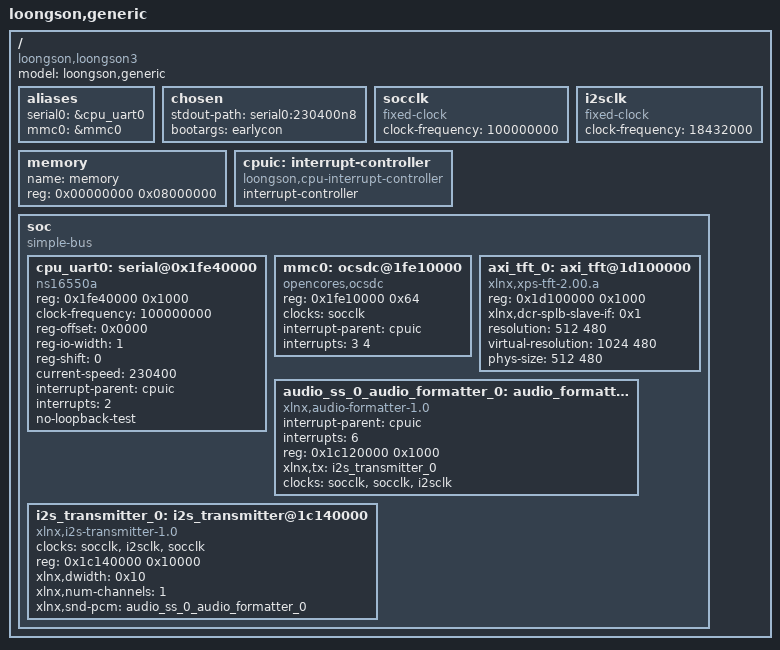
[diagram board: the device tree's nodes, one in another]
/dts-v1/;
/{
    model = "loongson,generic";
    compatible = "loongson,loongson3";
    #address-cells = <1>;
    #size-cells = <1>;

    aliases {
        serial0 = &cpu_uart0;
        mmc0 = &mmc0;
    };

    chosen {
        stdout-path = "serial0:230400n8";
        bootargs = "earlycon";
    };

	socclk: socclk {
		compatible = "fixed-clock";
		clock-frequency = <100000000>;
		#clock-cells = <0>;
	};

	i2sclk: i2sclk {
		compatible = "fixed-clock";
		clock-frequency = <18432000>;
		#clock-cells = <0>;
	};

    memory {
        name = "memory";
        device_type = "memory";
        reg =  <0x00000000  0x08000000>;
    };

	cpuic: interrupt-controller {
	    compatible = "loongson,cpu-interrupt-controller";
        interrupt-controller;
		#interrupt-cells = <1>;
	};

	soc {
		compatible = "simple-bus";
		#address-cells = <1>;
		#size-cells = <1>;
		ranges = <0x10000000 0x10000000 0x10000000>;

	    // axi_intc_0: interrupt-controller@1fb00000 {
	    // 	#interrupt-cells = <1>;
	    // 	compatible = "xlnx,xps-intc-1.00.a";
	    // 	interrupt-controller;
	    // 	interrupt-parent = <&cpuic>;
	    // 	interrupts = <2>;
	    // 	reg = <0x1fb00000 0x1000>;
	    // 	xlnx,kind-of-intr = <0x1>;
	    // 	xlnx,num-intr-inputs = <0x8>;
	    // };

        cpu_uart0: serial@0x1fe40000 {
		    device_type = "serial";
		    compatible = "ns16550a";
		    reg = <0x1fe40000 0x1000>;
            clock-frequency = <100000000>;
		    reg-offset = <0x0000>;
		    reg-io-width = <1>;
		    reg-shift = <0>;
		    current-speed = <230400>;
		    interrupt-parent = <&cpuic>;
		    interrupts = <2>;
            no-loopback-test;
        };

        mmc0: ocsdc@1fe10000 {
            compatible = "opencores,ocsdc";
            reg = <0x1fe10000 0x64>;
            clocks = <&socclk>;
            interrupt-parent = <&cpuic>;
            interrupts = <3 4>;
        };

        axi_tft_0: axi_tft@1d100000 {
			compatible = "xlnx,xps-tft-2.00.a";
			reg = <0x1d100000 0x1000>; // tft controller
			xlnx,dcr-splb-slave-if = <0x1>;
			resolution = <512 480>; // actual video size
			virtual-resolution = <1024 480>; // virtual framebuffer size
			phys-size = <512 480>; // physical size of screen (no use) 
		};

        // usb: usb@1c170000 {
		//     compatible = "ue11-hcd";
		//     reg = <0x1c170000 0x1000>;
		//     interrupt-parent = <&cpuic>;
		//     interrupts = <5>;
		// };

        audio_ss_0_audio_formatter_0: audio_formatter@1c120000 {
            compatible = "xlnx,audio-formatter-1.0";
            interrupt-names = "irq_mm2s";
            interrupt-parent = <&cpuic>;
            interrupts = <6>;
            reg = <0x1c120000 0x1000>;
            xlnx,tx = <&i2s_transmitter_0>;
            // xlnx,rx = <&i2s_receiver>;
            clock-names = "s_axi_lite_aclk", "m_axis_mm2s_aclk", "aud_mclk";
            clocks = <&socclk>, <&socclk>, <&i2sclk>;
        };

        i2s_transmitter_0: i2s_transmitter@1c140000 {
            compatible = "xlnx,i2s-transmitter-1.0";
            clock-names = "s_axi_ctrl_aclk", "aud_mclk", "s_axis_aud_aclk";
            clocks = <&socclk>, <&i2sclk>, <&socclk>;
            reg = <0x1c140000 0x10000>;
            xlnx,dwidth = <0x10>;
            xlnx,num-channels = <1>;
            xlnx,snd-pcm = <&audio_ss_0_audio_formatter_0>;
        };

        // reserved-memory {
        //     #address-cells = <1>;
        //     #size-cells = <1>;
        //     ranges;
            
        //     reserved: buffer@0 {
        //         no-map;
        //         reg = <0x07800000 0x00080000>;
        //     };
        // };

        // uio_0: uio_fb@1d100000 {
        //     compatible = "generic-uio";
        //     status = "okay";
        //     reg = <0x1d100000 0x1000>;
        // };

        // uio_1: uio_jpeg@1d110000 {
        //     compatible = "generic-uio";
        //     status = "okay";
        //     reg = <0x1d110000 0x1000>;
        // };

        // uio_0: uio_sm3@1d120000 {
        //     compatible = "generic-uio";
        //     status = "okay";
        //     reg = <0x1d120000 0x1000>;
        // };
    };
};

